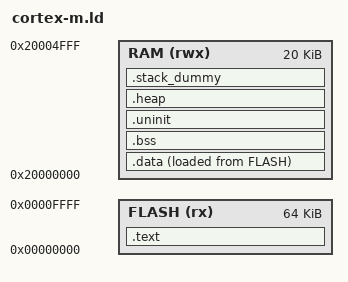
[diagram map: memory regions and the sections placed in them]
ENTRY(Reset_Handler)

MEMORY
{
    FLASH (rx) : ORIGIN = 0x00000000, LENGTH = 64K
    RAM (rwx) : ORIGIN = 0x20000000, LENGTH = 20K
}

SECTIONS
{
	.text :
	{
		KEEP(*(.exception_table))
		KEEP(*(.interrupt_table))

		*(.text*)
		*(.glue_7)
		*(.glue_7t)
	    *(.vfp11_veneer)
	    *(.v4_bx)
        *(.iplt)
        *(.rel.iplt)
        *(.igot.plt)

		*(.rodata*)

		KEEP(*(.init))
		KEEP(*(.fini))

		/* .ctors */
		*crtbegin.o(.ctors)
		*crtbegin?.o(.ctors)
		*(EXCLUDE_FILE(*crtend?.o *crtend.o) .ctors)
		*(SORT(.ctors.*))
		*(.ctors)

		/* .dtors */
 		*crtbegin.o(.dtors)
 		*crtbegin?.o(.dtors)
 		*(EXCLUDE_FILE(*crtend?.o *crtend.o) .dtors)
 		*(SORT(.dtors.*))
 		*(.dtors)

		KEEP(*(.eh_frame*))
	} > FLASH

	.data :
	{
		*(vtable)
		*(.data*)

		. = ALIGN(4);
		/* preinit data */
		PROVIDE_HIDDEN (__preinit_array_start = .);
		KEEP(*(.preinit_array))
		PROVIDE_HIDDEN (__preinit_array_end = .);

		. = ALIGN(4);
		/* init data */
		PROVIDE_HIDDEN (__init_array_start = .);
		KEEP(*(SORT(.init_array.*)))
		KEEP(*(.init_array))
		PROVIDE_HIDDEN (__init_array_end = .);


		. = ALIGN(4);
		/* finit data */
		PROVIDE_HIDDEN (__fini_array_start = .);
		KEEP(*(SORT(.fini_array.*)))
		KEEP(*(.fini_array))
		PROVIDE_HIDDEN (__fini_array_end = .);

		. = ALIGN(4);
		/* All data end */
		__copy_end__ = .;

	} > RAM AT>FLASH

	__copy_start__ = ADDR(.data);
	__copy_origin = LOADADDR(.data);

	.bss :
	{
		. = ALIGN(4);
		__bss_start__ = .;
		*(.bss*)
		*(COMMON)
		. = ALIGN(4);
		__bss_end__ = .;
	} > RAM

	.uninit :
	{
		. = ALIGN(4);
		*(.uninit*)
		. = ALIGN(4);
	} > RAM

	.heap (COPY):
	{
		__end__ = .;
		PROVIDE(end = .);
		*(.heap*)
		__HeapLimit = .;
	} > RAM

	/* .stack_dummy section doesn't contains any symbols. It is only
	 * used for linker to calculate size of stack sections, and assign
	 * values to stack symbols later */
	.stack_dummy (COPY):
	{
		*(.stack*)
	} > RAM

	/* Set stack top to end of RAM, and stack limit move down by
	 * size of stack_dummy section */
	__StackTop = ORIGIN(RAM) + LENGTH(RAM);
	__StackInit = __StackTop;
	__StackLimit = __StackTop - SIZEOF(.stack_dummy);
	PROVIDE(__stack = __StackTop);

	/* Check if data + heap + stack exceeds RAM limit */
	ASSERT(__StackLimit >= __HeapLimit, "region RAM overflowed with stack")

    /* ELF Sections */
    .comment 0 : { *(.comment) }
    .symtab 0 : { *(.symtab) }
    .strtab 0 : { *(.strtab) }
    .shstrtab 0 : { *(.shstrtab) }

    /* Dwarf Sections */
    .debug_loclists 0 : { *(.debug_loclists) }
    .debug_abbrev 0 : { *(.debug_abbrev) }
    .debug_info 0 : { *(.debug_info) }
    .debug_str_offsets 0 : { *(.debug_str_offsets) }
    .debug_str 0 : { *(.debug_str) }
    .debug_addr 0 : { *(.debug_addr) }
    .debug_frame 0 : { *(.debug_frame) }
    .debug_line 0 : { *(.debug_line) }
    .debug_line_str 0 : { *(.debug_line_str) }
    .debug_loc 0 : { *(.debug_loc) }
    .debug_ranges 0 : { *(.debug_ranges) }
    .debug_aranges 0 : { *(.debug_aranges) }
    .debug_macro 0 : { *(.debug_macro) }
    .debug_rnglists 0 : { *(.debug_rnglists) }

    /* Exceptions are disabled, we don't need these sections */
    /DISCARD/ : {
        *(.ARM.extab);
        *(.ARM.exidx);
        *(.ARM.attributes);
    }
}
